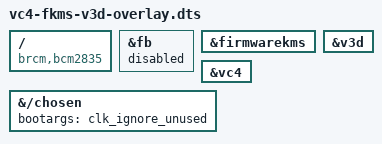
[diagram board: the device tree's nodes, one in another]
/*
 * vc4-fkms-v3d-overlay.dts
 */

#include "cma-overlay.dts"

/ {
	compatible = "brcm,bcm2835";

	fragment@1 {
		target = <&fb>;
		__overlay__  {
			status = "disabled";
		};
	};

	fragment@2 {
		target = <&firmwarekms>;
		__overlay__  {
			status = "okay";
		};
	};

	fragment@3 {
		target = <&v3d>;
		__overlay__  {
			status = "okay";
		};
	};

	fragment@4 {
		target = <&vc4>;
		__overlay__  {
			status = "okay";
		};
	};
	fragment@5 {
		target-path = "/chosen";
		__overlay__  {
			bootargs = "clk_ignore_unused";
		};
	};
};
